# netx90_app register map
File version: 1.0
CPU: CM4 r0p1, little endian, MPU, FPU, 4 interrupt priority bits, 78 interrupts
Registers are 32-bit, read-write, reset 0x0 unless marked. A register's access mark holds for its fields unless they carry their own. Offsets are from the block's base; [hi:lo] are bit positions; {n}, {i} and the like mark numbered series; <NAME> marks a mode.

## hif_sdram_ctrl
Base 0xFF401540
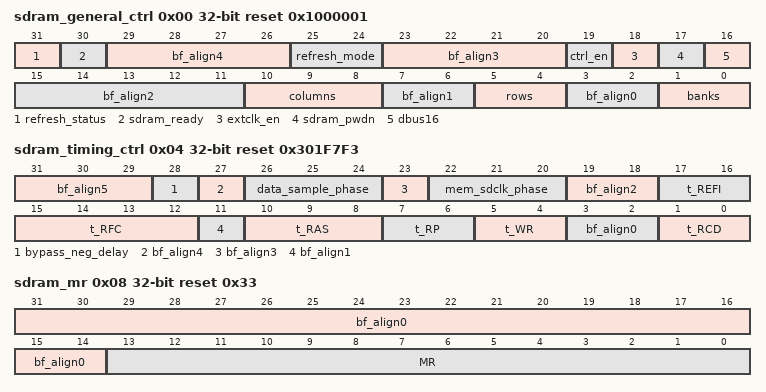
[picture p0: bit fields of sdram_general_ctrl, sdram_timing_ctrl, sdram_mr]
0x00 sdram_general_ctrl reset 0x1000001 (reset mask 0xC30F0733) — Control Register for external SDRAM access. For initializing procedure netX SDRAM controller view description of 'ctrl_en' bit inside this register. Note: This register can be protected by the register MODULE_FIREWALL_CTRL.firewall_cfg_hifmemctrl.
  [31] refresh_status — Refresh status flag. Refresh behaviour changed from netx100/500/50: SDRAM controller now has an additional high priority refresh mode (view refresh_mode bit description). There is no need to guarantee sufficient SDRAM refresh generation by checking this bit by software any longer (necessary for netx100/500/50 depending on application). It is only for information purpose for netX10 or later. This bit can be reset by writing '0' to it. Note: This bit is writable but can also be changed by hardware.
  [30] sdram_ready — SDRAM ready. This bit is set to 1 if SDRAM is ready for access. If sdram_general_ctrl.ctrl_en == 0 or sdram_general_ctrl.sdram_pwdn == 0 sdram_ready will be low. It will be set to 1 after SDRAM has been initialized or after power down wake up. Note: This bit is a read only status flag.
  [29:26] bf_align4 — bitField alignment value for aeabi compatibility
  [25:24] refresh_mode — Refresh request generation mode. Refresh behaviour changed from netx100/500/50: SDRAM controller now has an additional high priority refresh mode. Refresh generation has lower priority than accesses on external memory interface normally. That means refreshes do not block data access. To avoid data loss under all conditions without checking critical situations by software a high priority refresh mode is implemented for netX10 and later: If there was too much traffic to SDRAM to run refreshes according to programmed refresh_mode the controller changes to high priority refresh mode automatically. In this mode the controller generates immediately as many refreshes as required to avoid imminent data loss. After that the controller falls back to low priority refresh generation automatically. In normal low priority refresh mode refreshes can be collected. That means single refreshes are not necessarily done in programmed average refresh interval (t_REFI in sdram_timing_ctrl register). However the controller ensures by hardware that t_REFI is kept as mean refresh interval for a certain number of subsequent refreshes. This number of refreshes that will be collected to a long term refresh sequence can be programmed in this bit field. The following refresh request generation mode can be programmed: 00 : fix interval: expect one refresh any programmed refresh period (sdram_timing_ctrl.t_REFI) 01 : collect up to 8 refreshes (default) 10 : collect up to 16 refreshes 11 : collect up to 2047 refreshes Note: Typically SDRAM devices do not require a fix refresh interval. Collecting more refreshes will lead to improved performance (as high priority refresh mode blocking normal access is entered more often when only few refreshes can be collected). Hence, it is recommended setting this bit field to '11' (collecting up to 2047 refreshes). Note: Entering high priority refresh mode typically occurs when SDRAM becomes system performance bottleneck. To detect this, a status bit (refresh_status) will be set when high priority refresh mode was entered. It can be used for debugging or system status information purpose.
  [23:20] bf_align3 — bitField alignment value for aeabi compatibility
  [19] ctrl_en — Global SDRAM controller enable. Note: The sdram_timing_ctrl and the sdram_mr register can only be changed while this bit is 0. Initializing and enabling SDRAM should be done as follows: { | A. Special attention must be done before enabling SDRAM after netX reset without power supply was disabled (e.g. pressing some kind of reset button). In this case a reset could be done while a SDRAM read burst was performed. As SDRAM clock will be disabled immediately in case of reset external SDRAM device will keep driving data-lines. To free data lines at least 10 SDRAM clock cycles must be performed. This should be done by enabling (extclk_en-bit set and ctrl_en-bit set) the controller and disabling again (ctrl_en-bit cleared) before really enabling SDRAM and before any other access to external memory devices sharing SDRAM data-lines (e.g. parallel flash devices). B. If SDRAM was already enabled: Disable SDRAM controller by setting the ctrl_en-bit to 0. Ensure that no netX system master is trying to access SDRAM address area. Otherwise related master will be stalled (no ready) until re-enabling SDRAM. 1. Configure the sdram_timing_ctrl register: All timing parameters of the t_* bit fields must be taken from SDRAM device data sheet. All other timing parameters like clock and sample phases are provided by Hilscher. 2. Configure the sdram_mr register: Typically only setting of correct CAS-Latency is required (CL2 or CL3 supported by netX SDRAM controller). CL2 provides better performance an should be preferred. Please read description of the sdram_mr register for further details. 3. Configure the sdram_general_ctrl (this) register and enable the controller by setting the 'ctrl_en' bit. The values for 'banks', 'rows' and 'columns' depend on the used SDRAM device and must be taken from the related data sheet. 4. Wait until 'sdram_ready' status bit is set before accessing SDRAM device. } ------------------------------------ After enable, the controller will run the following SDRAM initialisation procedure (100MHz, 1 cycle = 10ns). { | | | command cycles time comment NOP 20050 200.5us running sd_clk (if extclk_en), *cs low, cke high) PRECH ALL, NOP 1+15 10ns + 150ns 7x(AUTO REF, NOP) 7x(1+31) 7x(10ns + 310ns) AUTO REF, NOP 1+22 10ns + 220ns LOAD MREG, NOP 1+3 10ns + 30ns with settings done by the sdram_mr registers ACTIVATE 1 10ns first access if requested, sdram_ready will be set to 1 here } ------------------------------------ Attention: Accesses requested to SDRAM address area when the controller is not enabled or before SDRAM initialisation procedure was finished (before sdram_ready bit is 1) will be blocked (no ready). This could cause system freezing. Note: The external SDRAM clock will not run if the controller is disabled.
  [18] extclk_en — external SDRAM clock enable 0 : SDRAM clock disabled (default) 1 : SDRAM clock enabled Note: The external SDRAM clock will not run if the controller is disabled.
  [17] sdram_pwdn — SDRAM power down If this bit is set, the controller will move SDRAM to power down self refresh mode (no data loss) and stop the external SDRAM clock. Return from power-down mode can be done by clearing this bit.
  [16] dbus16 — SDRAM data bus width 0 : SDRAM data bus is 8 bit wide (default) 1 : SDRAM data bus is 16 bit wide
  [15:11] bf_align2 — bitField alignment value for aeabi compatibility
  [10:8] columns — Number of SDRAM device columns and address lines. 000 : 256 columns, address lines A0..A7 (default) 001 : 512 columns, address lines A0..A8 010 : 1k columns, address lines A0..A9 011 : 2k columns, address lines A0..A9,A11 100 : 4k columns, address lines A0..A9,A11,A12 All others: reserved
  [7:6] bf_align1 — bitField alignment value for aeabi compatibility
  [5:4] rows — Number of SDRAM device rows and address lines. 00 : 2k rows, address lines A0..A10 (default) 01 : 4k rows, address lines A0..A11 10 : 8k rows, address lines A0..A12
  [3:2] bf_align0 — bitField alignment value for aeabi compatibility
  [1:0] banks — Number of SDRAM device banks and address lines. 00 : 2 banks, address (BA0) 01 : 4 banks, address lines (BA1, BA0)(default) All others: reserved
0x04 sdram_timing_ctrl reset 0x301F7F3 (reset mask 0x1773F7F3) — Control Register for external SDRAM access. Changes can only be done, if the SDRAM controller is disabled (sdram_general_ctrl.ctrl_en == 0) to avoid configuration problems. Please view description of 'ctrl_en' bit inside sdram_general_ctrl register for initializing-procedure of netX SDRAM controller. Note: This register can be protected by the register MODULE_FIREWALL_CTRL.firewall_cfg_hifmemctrl. Note: For some registers the reset-value is a reserved value. I.e. these registers must be programmed to another value than the reset-value at initialization (e.g. t_WR). The values with the remark '(default)' are the values which should be applicable for all SDRAM devices. However it is strongly recommended to set the values best-fitting the connected device as the default values typically lead to an immense performance penalty (e.g. t_RAS default is 10).
  [31:29] bf_align5 — bitField alignment value for aeabi compatibility
  [28] bypass_neg_delay — Bypass data sample clock phase shift. 0: use phase shifted (negative delayed) SDRAM loopback clock for data sampling. 1: bypass phase shift logic for SDRAM data sampling. Use SDRAM loopback clock for data sampling. Bypass must be used for system clock frequencies <= 80MHz (rate_mull_add <= 0xC0). If this bit is programmed with '0' by software but system clock frequency is below 80MHz, it will be changed to '1' to enable bypass automatically. When system frequency is changed to a rate more than 80MHz, the bit is released to '0' again. This allows entering netX power save mode entry and leave without reconfiguring this bit by software. However take care that no SDRAM access is running at the moment of system clock frequency change around the 80MHz border. Note: The bit will always remain '1' if it is programmed high. Note: This bit is writable but can also be changed by hardware.
  [27] bf_align4 — bitField alignment value for aeabi compatibility
  [26:24] data_sample_phase — Data sample clock phase shift. 0..5: adjustable phase-shift for data sampling SDRAM loopback clock (clk_sdloopback) depending on external capacitive load and SDRAM access time (t_AC). The phase can be shifted in 1.25ns steps. clk_sdloopback will internally rise (sample SDRAM read data) at the data_sample_phase+4th clk400 edge after rise of external MEM_SDCLK (including external capacitive load). For correct settings, the delays depending on external capacitive have to be respected. Data sampling has to be done at least 8ns after internal changes of SDRAM ctrl-signals (MEM_SD*-signals, driven by clk_memsig).
  [23] bf_align3 — bitField alignment value for aeabi compatibility
  [22:20] mem_sdclk_phase — MEM_SDCLK phase shift. 0..5: adjustable phase-shift for external SDRAM clock depending on external capacitive load on MEM_SDCLK-signal to match SDRAM signals setup times. The phase can be shifted in 1.25ns steps. MEM_SDCLK will internally rise at the mem_sdclk_phase+1st clk400 edge after internal changes of SDRAM signals (MEM_SD*-signals, MI address and data buses driven by clk_memsig) For correct settings delays depending on external capacitive load have to be respected. Note: The phase shift logic was optimized. Since netX90: - the mem_sdclk_ssneg-bit is obsolete. - phase shift now can be done by (0..5)*1.25ns + 1.25ns, previousely: (0..5)*1.25ns + 2.5ns
  [19:18] bf_align2 — bitField alignment value for aeabi compatibility
  [17:16] t_REFI — Average periodic refresh interval (3.90 us * 2^t_REFI 00 : 3.90 us 01 : 7.80 us (default) 10 : 15.60 us 11 : 31.20 us Note: Typically refresh of SDRAM devices is specified by a certain number of refreshes that must be performed within a certain time. E.g. 8192 refreshes for 64ms. Dividing the time by the number of refreshes leads to the average periodic refresh interval. E.g. 64ms/8192 = 7.8us. Please view also description of 'refresh_mode' of 'sdram_general_ctrl' register for details.
  [15:12] t_RFC — REFRESH to next command time (clk = tRFC + 4) 0000 : 4 clks 0001 : 5 clks and so on 1111 : 19 clks (default)
  [11] bf_align1 — bitField alignment value for aeabi compatibility
  [10:8] t_RAS — ACTIVE to PRECHARGE command time (clk = t_RAS + 3) 000 : 3 clks 001 : 4 clks and so on 111 : 10 clks (default) Note: If Active-to-Active-command-period (t_RC) exceeds t_RAS+t_RP, set t_RAS and t_RP in a way that the following condition is met: t_RAS+t_RP>=t_RC.
  [7:6] t_RP — Precharge command period time (PRECHARGE to next command) 00 : 1 clk 01 : 2 clks 10 : 3 clks (default) 11 : reserved Note: For Active-to-Active-command-period (t_RC) view note at t_RAS.
  [5:4] t_WR — Write recovery time (last write data to PRECHARGE) 00 : 1 clk 01 : 2 clks 10 : 3 clks (default) 11 : reserved
  [3:2] bf_align0 — bitField alignment value for aeabi compatibility
  [1:0] t_RCD — ACTIVE to READ or WRITE time (RAS to CAS, clk = t_RCD) This value will be also taken as t_RRD (ACTIVE bank A to ACTIVE bank B time) 00 : 1 clk 01 : 2 clks 10 : 3 clks (default) 11 : reserved
0x08 sdram_mr reset 0x33 (reset mask 0x3FFF) — Mode Register for SDRAM device. Changes can only be done, if the SDRAM controller is disabled (sdram_general_ctrl.ctrl_en == 0) to avoid configuration problems. The SDRAM Mode Registers of the used SDRAM device will be set after enabling the SDRAM controller in the 200us SDRAM memory initialisation procedure. It is part of the SDRAM device and programmed by the LOAD MODE REGISTER command. For details of SDRAM Mode Register view datasheet of used SDRAM device. Please view description of 'ctrl_en' bit inside sdram_general_ctrl register for initializing-procedure of netX SDRAM controller. Note: This register can be protected by the register MODULE_FIREWALL_CTRL.firewall_cfg_hifmemctrl.
  [31:14] bf_align0 — bitField alignment value for aeabi compatibility
  [13:0] MR — SDRAM Mode Register. CAS latency bits are typically located in MR[6:4]. Only CL2 and CL3 are supported, not CL1; default is CL3 Burst Length in MR[2:0] is read only here. Burst length depends on data bus width programmed in sdram_general_ctrl.dbus16 register bit The netX10 controller supports only Burst Length 8 (default) for 8bit SDRAM interface and 4 for 16bit SDRAM interface. Note: SDRAM devices where burst length is not located in Mode Register bits MR[2:0] are not supported by netX SDRAM controller. However these devices are not common. Note: This bit is writable but can also be changed by hardware.
